# WLR089U0 register map
Vendor: Microchip Technology; Series: WLR089; File version: 0
CPU: CM0+ r0p0, selectable endian, no MPU, no FPU, VTOR, 2 interrupt priority bits
Registers are 32-bit, read-write, reset 0x0 unless marked. A register's access mark holds for its fields unless they carry their own. Offsets are from the block's base; [hi:lo] are bit positions; {n}, {i} and the like mark numbered series; 'fields as' and 'values as' point back to an identical list.

## EIC — External Interrupt Controller
Base 0x40002400; register names take the prefix EIC_
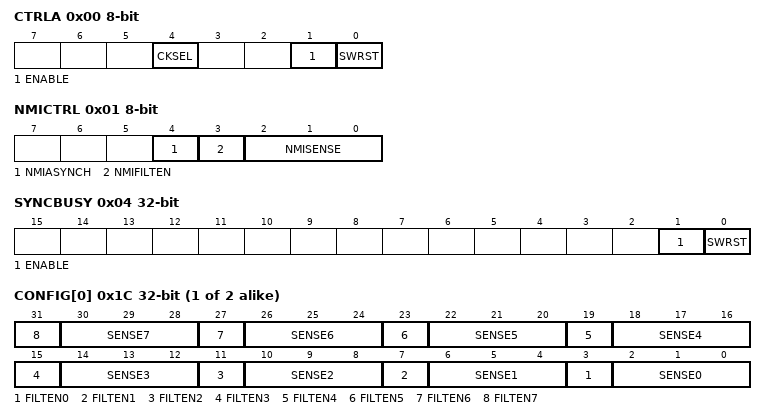
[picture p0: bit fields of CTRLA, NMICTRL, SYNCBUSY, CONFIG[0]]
0x00 CTRLA 8-bit — Control
  [4] CKSEL — Clock Selection
    0=CLK_GCLK (Clocked by GCLK); 1=CLK_ULP32K (Clocked by ULP32K)
  [1] ENABLE
  [0] SWRST — Software Reset
0x01 NMICTRL 8-bit — NMI Control
  [4] NMIASYNCH — NMI Asynchronous edge Detection Enable
    0=SYNC (Edge detection is clock synchronously operated); 1=ASYNC (Edge detection is clock asynchronously operated)
  [3] NMIFILTEN — NMI Filter Enable
  [2:0] NMISENSE — NMI Input Sense Configuration
    0=NONE (No detection); 1=RISE (Rising edge detection); 2=FALL (Falling edge detection); 3=BOTH (Both edges detection); 4=HIGH (High level detection); 5=LOW (Low level detection)
0x02 NMIFLAG 16-bit — NMI Interrupt Flag
  [0] NMI
0x04 SYNCBUSY ro
  [1] ENABLE — Enable synchronisation
  [0] SWRST — Software reset synchronisation
0x08 EVCTRL — Event Control
  [15:0] EXTINTEO — External Interrupt Event Output Enable
0x0C INTENCLR — Interrupt Enable Clear
  [15:0] EXTINT — External Interrupt Disable
0x10 INTENSET — Interrupt Enable Set
  [15:0] EXTINT — External Interrupt Enable
0x14 INTFLAG — Interrupt Flag Status and Clear
  [15:0] EXTINT — External Interrupt Flag
0x18 ASYNCH — EIC Asynchronous edge Detection Enable
  [15:0] ASYNCH
    values as NMICTRL.NMIASYNCH
{0x1C+4i} CONFIG[{i}] (i=0..1) — Configuration n
  [4n+3] FILTEN{n} (n=0..7) — Filter Enable {n}
  [4n+2:4n] SENSE{n} (n=0..7) — Input Sense Configuration {n}
    values as NMICTRL.NMISENSE

## EVSYS — Event System Interface
Base 0x43000000; register names take the prefix EVSYS_
0x00 CTRLA 8-bit — Control
  [0] SWRST — Software Reset
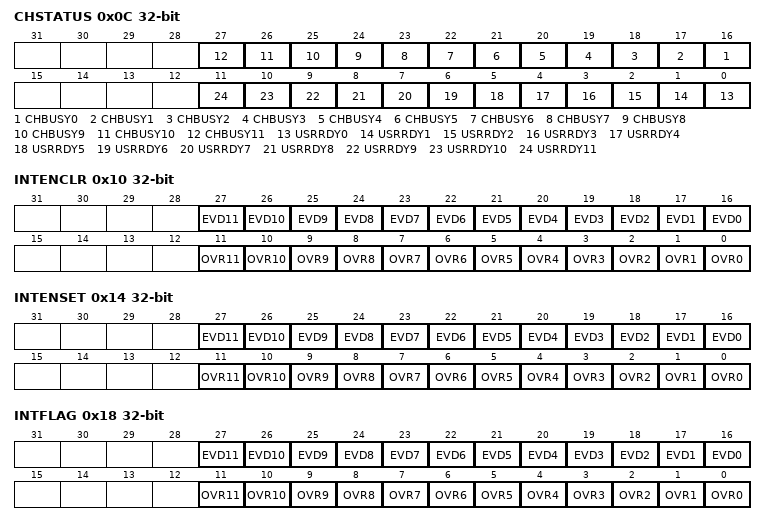
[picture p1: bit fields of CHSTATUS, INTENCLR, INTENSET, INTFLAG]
0x0C CHSTATUS ro — Channel Status
  [n+16] CHBUSY{n} (n=0..11) — Channel {n} Busy
  [n] USRRDY{n} (n=0..11) — Channel {n} User Ready
0x10 INTENCLR — Interrupt Enable Clear
  [n+16] EVD{n} (n=0..11) — Channel {n} Event Detection Interrupt Enable
  [n] OVR{n} (n=0..11) — Channel {n} Overrun Interrupt Enable
0x14 INTENSET — Interrupt Enable Set
  fields as INTENCLR
0x18 INTFLAG — Interrupt Flag Status and Clear
  [n+16] EVD{n} (n=0..11) — Channel {n} Event Detection
  [n] OVR{n} (n=0..11) — Channel {n} Overrun
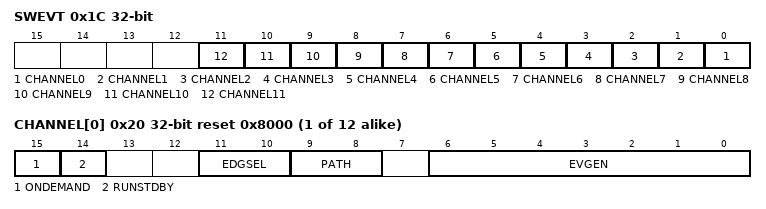
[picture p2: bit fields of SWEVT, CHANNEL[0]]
0x1C SWEVT wo — Software Event
  [n] CHANNEL{n} (n=0..11) — Channel {n} Software Selection
{0x20+4i} CHANNEL[{i}] (i=0..11) reset 0x8000 — Channel n
  [15] ONDEMAND — Generic Clock On Demand
  [14] RUNSTDBY — Run in standby
  [11:10] EDGSEL — Edge Detection Selection
    0=NO_EVT_OUTPUT (No event output when using the resynchronized or synchronous path); 1=RISING_EDGE (Event detection only on the rising edge of the signal from the event generator when using the resynchronized or synchronous path); 2=FALLING_EDGE (Event detection only on the falling edge of the signal from the event generator when using the resynchronized or synchronous path); 3=BOTH_EDGES (Event detection on rising and falling edges of the signal from the event generator when using the resynchronized or synchronous path)
  [9:8] PATH — Path Selection
    0=SYNCHRONOUS (Synchronous path); 1=RESYNCHRONIZED (Resynchronized path); 2=ASYNCHRONOUS (Asynchronous path)
  [6:0] EVGEN — Event Generator Selection
{0x80+4i} USER[{i}] (i=0..44) — User Multiplexer n
  [4:0] CHANNEL — Channel Event Selection

## GCLK — Generic Clock Generator
Base 0x40001800; register names take the prefix GCLK_
0x00 CTRLA 8-bit — Control
  [0] SWRST — Software Reset
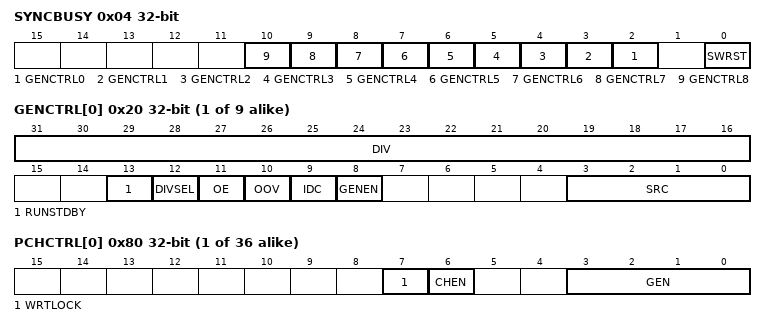
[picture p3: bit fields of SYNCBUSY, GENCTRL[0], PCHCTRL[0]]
0x04 SYNCBUSY ro — Synchronization Busy
  [n+2] GENCTRL{n} (n=0..8) — Generic Clock Generator Control {n} Synchronization Busy bits
    1=GCLK0 (Generic clock generator 0); 2=GCLK1 (Generic clock generator 1); 4=GCLK2 (Generic clock generator 2); 8=GCLK3 (Generic clock generator 3); 16=GCLK4 (Generic clock generator 4); 32=GCLK5 (Generic clock generator 5); 64=GCLK6 (Generic clock generator 6); 128=GCLK7 (Generic clock generator 7); 0x100=GCLK8 (Generic clock generator 8)
  [0] SWRST — Software Reset Synchroniation Busy bit
{0x20+4i} GENCTRL[{i}] (i=0..8) — Generic Clock Generator Control
  [31:16] DIV — Division Factor
  [13] RUNSTDBY — Run in Standby
  [12] DIVSEL — Divide Selection
    0=DIV1 (Divide input directly by divider factor); 1=DIV2 (Divide input by 2^(divider factor+ 1))
  [11] OE — Output Enable
  [10] OOV — Output Off Value
  [9] IDC — Improve Duty Cycle
  [8] GENEN — Generic Clock Generator Enable
  [3:0] SRC — Source Select
    0=XOSC (XOSC oscillator output); 1=GCLKIN (Generator input pad); 2=GCLKGEN1 (Generic clock generator 1 output); 3=OSCULP32K (OSCULP32K oscillator output); 4=OSC32K (OSC32K oscillator output); 5=XOSC32K (XOSC32K oscillator output); 6=OSC16M (OSC16M oscillator output); 7=DFLL48M (DFLL48M output); 8=DPLL96M (DPLL96M output)
{0x80+4i} PCHCTRL[{i}] (i=0..35) — Peripheral Clock Control
  [7] WRTLOCK — Write Lock
  [6] CHEN — Channel Enable
  [3:0] GEN — Generic Clock Generator
    {v}=GCLK{v} (Generic clock generator {v}) (v=0..8)
